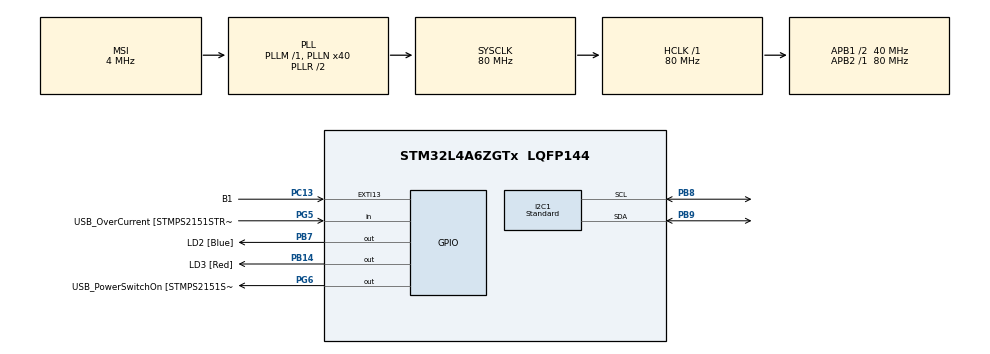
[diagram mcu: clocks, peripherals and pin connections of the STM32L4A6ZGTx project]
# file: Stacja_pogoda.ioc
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Mcu.Family=STM32L4
Dma.I2C1_TX.0.Instance=DMA1_Channel6
RCC.CortexFreq_Value=80000000
PG6.Signal=GPIO_Output
NVIC.I2C1_EV_IRQn=true\:0\:0\:false\:false\:true\:true\:true
I2C1.I2C_Speed_Mode=I2C_Standard
VP_ADC1_TempSens_Input.Mode=IN-TempSens
Dma.I2C1_TX.0.PeriphDataAlignment=DMA_PDATAALIGN_BYTE
PG8.Signal=LPUART1_RX
PB14.GPIO_Label=LD3 [Red]
Dma.I2C1_TX.0.Direction=DMA_MEMORY_TO_PERIPH
PG6.GPIO_Label=USB_PowerSwitchOn [STMPS2151STR_EN]
PC13.GPIO_Label=B1
PG5.GPIO_Label=USB_OverCurrent [STMPS2151STR_FAULT]
PB11.Signal=I2C2_SDA
RCC.SYSCLKSource=RCC_SYSCLKSOURCE_PLLCLK
ProjectManager.StackSize=0x400
PA14\ (JTCK/SWCLK).Signal=SYS_JTCK-SWCLK
PA12.Signal=USB_OTG_FS_DP
RCC.HCLKFreq_Value=80000000
RCC.APB2TimFreq_Value=80000000
Dma.I2C1_TX.0.Priority=DMA_PRIORITY_LOW
RCC.AHBFreq_Value=80000000
ADC1.Channel-0\#ChannelRegularConversion=ADC_CHANNEL_TEMPSENSOR
RCC.HSE_VALUE=8000000
PA13\ (JTMS/SWDIO).GPIO_Label=TMS
Dma.I2C1_TX.0.MemInc=DMA_MINC_ENABLE
PA10.GPIO_Label=USB_ID
PB7.Signal=GPIO_Output
PA8.Signal=USB_OTG_FS_SOF
PA14\ (JTCK/SWCLK).Mode=Trace_Asynchronous_SW
ADC1.SamplingTime-0\#ChannelRegularConversion=ADC_SAMPLETIME_2CYCLES_5
PB7.GPIO_Label=LD2 [Blue]
Dma.I2C1_TX.0.PeriphInc=DMA_PINC_DISABLE
PB9.Signal=I2C1_SDA
Mcu.Package=LQFP144
PA10.Signal=USB_OTG_FS_ID
Dma.I2C1_TX.0.MemDataAlignment=DMA_MDATAALIGN_BYTE
PB8.GPIO_PuPdOD=GPIO_NOPULL
PA14\ (JTCK/SWCLK).GPIO_Label=TCK
RCC.APB1TimFreq_Value=80000000
Dma.I2C1_TX.0.Mode=DMA_NORMAL
I2C1.CustomTiming=Enabled
Dma.Request0=I2C1_TX
RCC.HSI48_VALUE=48000000
RCC.PLLSAI1N=16
PB3\ (JTDO/TRACESWO).GPIO_Label=SWO
RCC.MSI_VALUE=4000000
NVIC.DMA1_Channel6_IRQn=true\:0\:0\:false\:false\:true\:false\:true
ADC1.Rank-0\#ChannelRegularConversion=1
PG7.Signal=LPUART1_TX
PA13\ (JTMS/SWDIO).Mode=Trace_Asynchronous_SW
PG5.Signal=GPIO_Input
ADC1.OffsetNumber-0\#ChannelRegularConversion=ADC_OFFSET_NONE
PC13.Signal=GPXTI13
PA9.GPIO_Label=USB_VBUS
PA11.GPIO_Label=USB_DM
PC15-OSC32_OUT\ (PC15).Signal=RCC_OSC32_OUT
RCC.APB1CLKDivider=RCC_HCLK_DIV2
PA12.GPIO_Label=USB_DP
PH1-OSC_OUT\ (PH1).Signal=RCC_OSC_OUT
PG8.GPIO_Label=STLK_TX [STM32F103CBT6_PA2]
PA8.GPIO_Label=USB_SOF [TP1]
PB3\ (JTDO/TRACESWO).Signal=SYS_JTDO-SWO
ProjectManager.TargetToolchain=STM32CubeIDE
PB9.Mode=I2C
PA9.Signal=USB_OTG_FS_VBUS
I2C1.Timing=0x00909BEB
RCC.USBFreq_Value=32000000
RCC.LSE_VALUE=32768
PB10.Signal=I2C2_SCL
PB14.Signal=GPIO_Output
board=NUCLEO-L4A6ZG
RCC.VCOOutputFreq_Value=160000000
RCC.APB2Freq_Value=80000000
PG7.GPIO_Label=STLK_RX [STM32F103CBT6_PA3]
RCC.ADCFreq_Value=32000000
Mcu.Name=STM32L4A6ZGTx
RCC.SYSCLKFreq_VALUE=80000000
ADC1.master=1
PC14-OSC32_IN\ (PC14).Signal=RCC_OSC32_IN
PA11.Signal=USB_OTG_FS_DM
ProjectManager.HeapSize=0x200
PB9.GPIO_PuPdOD=GPIO_NOPULL
RCC.HSI_VALUE=16000000
NVIC.PriorityGroup=NVIC_PRIORITYGROUP_4
ADC1.NbrOfConversionFlag=1
RCC.PLLN=40
PB8.Mode=I2C
PB3\ (JTDO/TRACESWO).Mode=Trace_Asynchronous_SW
PB8.Signal=I2C1_SCL
RCC.APB1Freq_Value=40000000
PA13\ (JTMS/SWDIO).Signal=SYS_JTMS-SWDIO

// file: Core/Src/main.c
/* USER CODE BEGIN Header */
/**
  ******************************************************************************
  * @file           : main.c
  * @brief          : Main program body
  ******************************************************************************
  * @attention
  *
  * <h2><center>&copy; Copyright (c) 2021 STMicroelectronics.
  * All rights reserved.</center></h2>
  *
  * This software component is licensed by ST under BSD 3-Clause license,
  * the "License"; You may not use this file except in compliance with the
  * License. You may obtain a copy of the License at:
  *                        opensource.org/licenses/BSD-3-Clause
  *
  ******************************************************************************
  */
/* USER CODE END Header */
#include "main.h"
#include "adc.h"
#include "dma.h"
#include "i2c.h"
#include "gpio.h"

/* USER CODE BEGIN Includes */
#include "ssd1306.h"
#include "font_ascii_5x7.h"
#include "GFX.h"
/* USER CODE END Includes */

void SystemClock_Config(void);

int main(void)
{

  /* MCU Configuration--------------------------------------------------------*/

  /* Reset of all peripherals, Initializes the Flash interface and the Systick. */
  HAL_Init();

  /* Configure the system clock */
  SystemClock_Config();

  /* Initialize all configured peripherals */
  MX_GPIO_Init();
  MX_DMA_Init();
  MX_I2C1_Init();
  MX_ADC1_Init();

  /* Infinite loop */
  /* USER CODE BEGIN WHILE */
  SSD1306_init();
  HAL_Delay (2000);
  GFX_draw_string(0, 56, (unsigned char *)"Osmy", WHITE, BLACK, 1, 1);
  GFX_draw_string(0, 48, (unsigned char *)"Siodmy", WHITE, BLACK, 1, 1);
  GFX_draw_string(0, 40, (unsigned char *)"Szosty", WHITE, BLACK, 1, 1);
  GFX_draw_string(0, 32, (unsigned char *)"Piąty", WHITE, BLACK, 1, 1);
  GFX_draw_string(0, 24, (unsigned char *)"Czwarty", WHITE, BLACK, 1, 1);
  GFX_draw_string(0, 16, (unsigned char *)"Trzeci", WHITE, BLACK, 1, 1);
  GFX_draw_string(0, 8, (unsigned char *)"Drugi", WHITE, BLACK, 1, 1);
  GFX_draw_string(0, 0, (unsigned char *)"Pierszy", WHITE, BLACK, 1, 1);

  SSD1306_display_repaint();

  while (1)
  {

    /* USER CODE END WHILE */

  }
}

void SystemClock_Config(void)
{
  RCC_OscInitTypeDef RCC_OscInitStruct = {0};
  RCC_ClkInitTypeDef RCC_ClkInitStruct = {0};
  RCC_PeriphCLKInitTypeDef PeriphClkInit = {0};

  /** Initializes the RCC Oscillators according to the specified parameters
  * in the RCC_OscInitTypeDef structure.
  */
  RCC_OscInitStruct.OscillatorType = RCC_OSCILLATORTYPE_MSI;
  RCC_OscInitStruct.MSIState = RCC_MSI_ON;
  RCC_OscInitStruct.MSICalibrationValue = 0;
  RCC_OscInitStruct.MSIClockRange = RCC_MSIRANGE_6;
  RCC_OscInitStruct.PLL.PLLState = RCC_PLL_ON;
  RCC_OscInitStruct.PLL.PLLSource = RCC_PLLSOURCE_MSI;
  RCC_OscInitStruct.PLL.PLLM = 1;
  RCC_OscInitStruct.PLL.PLLN = 40;
  RCC_OscInitStruct.PLL.PLLP = RCC_PLLP_DIV2;
  RCC_OscInitStruct.PLL.PLLQ = RCC_PLLQ_DIV2;
  RCC_OscInitStruct.PLL.PLLR = RCC_PLLR_DIV2;
  if (HAL_RCC_OscConfig(&RCC_OscInitStruct) != HAL_OK)
  {
    Error_Handler();
  }
  /** Initializes the CPU, AHB and APB buses clocks
  */
  RCC_ClkInitStruct.ClockType = RCC_CLOCKTYPE_HCLK|RCC_CLOCKTYPE_SYSCLK
                              |RCC_CLOCKTYPE_PCLK1|RCC_CLOCKTYPE_PCLK2;
  RCC_ClkInitStruct.SYSCLKSource = RCC_SYSCLKSOURCE_PLLCLK;
  RCC_ClkInitStruct.AHBCLKDivider = RCC_SYSCLK_DIV1;
  RCC_ClkInitStruct.APB1CLKDivider = RCC_HCLK_DIV2;
  RCC_ClkInitStruct.APB2CLKDivider = RCC_HCLK_DIV1;

  if (HAL_RCC_ClockConfig(&RCC_ClkInitStruct, FLASH_LATENCY_4) != HAL_OK)
  {
    Error_Handler();
  }
  PeriphClkInit.PeriphClockSelection = RCC_PERIPHCLK_I2C1|RCC_PERIPHCLK_ADC;
  PeriphClkInit.I2c1ClockSelection = RCC_I2C1CLKSOURCE_PCLK1;
  PeriphClkInit.AdcClockSelection = RCC_ADCCLKSOURCE_PLLSAI1;
  PeriphClkInit.PLLSAI1.PLLSAI1Source = RCC_PLLSOURCE_MSI;
  PeriphClkInit.PLLSAI1.PLLSAI1M = 1;
  PeriphClkInit.PLLSAI1.PLLSAI1N = 16;
  PeriphClkInit.PLLSAI1.PLLSAI1P = RCC_PLLP_DIV2;
  PeriphClkInit.PLLSAI1.PLLSAI1Q = RCC_PLLQ_DIV2;
  PeriphClkInit.PLLSAI1.PLLSAI1R = RCC_PLLR_DIV2;
  PeriphClkInit.PLLSAI1.PLLSAI1ClockOut = RCC_PLLSAI1_ADC1CLK;
  if (HAL_RCCEx_PeriphCLKConfig(&PeriphClkInit) != HAL_OK)
  {
    Error_Handler();
  }
  /** Configure the main internal regulator output voltage
  */
  if (HAL_PWREx_ControlVoltageScaling(PWR_REGULATOR_VOLTAGE_SCALE1) != HAL_OK)
  {
    Error_Handler();
  }
}

void Error_Handler(void)
{
  __disable_irq();
  while (1)
  {
  }
}

/************************ (C) COPYRIGHT STMicroelectronics *****END OF FILE****/
